# ATmega2564RFR2 register map
Vendor: Atmel; File version: 1.0
CPU: other r0p0, little endian, no MPU, no FPU, 4 interrupt priority bits
Registers are 8-bit, read-write, reset 0x0 unless marked. A register's access mark holds for its fields unless they carry their own. Offsets are from the block's base; [hi:lo] are bit positions; 'fields as' and 'values as' point back to an identical list.

## TC1 — Timer/Counter, 16-bit
Base 0x00800036
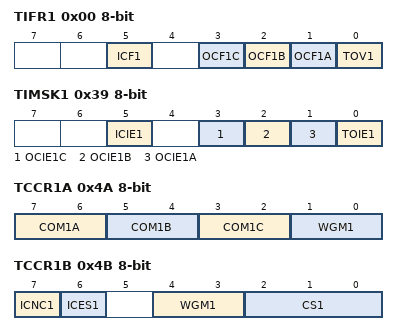
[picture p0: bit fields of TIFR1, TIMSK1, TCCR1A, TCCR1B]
0x00 TIFR1 — Timer/Counter1 Interrupt Flag Register (read-only for debugger)
  [5] ICF1 — Timer/Counter1 Input Capture Flag
  [3] OCF1C — Timer/Counter1 Output Compare C Match Flag
  [2] OCF1B — Timer/Counter1 Output Compare B Match Flag
  [1] OCF1A — Timer/Counter1 Output Compare A Match Flag
  [0] TOV1 — Timer/Counter1 Overflow Flag
0x39 TIMSK1 — Timer/Counter1 Interrupt Mask Register
  [5] ICIE1 — Timer/Counter1 Input Capture Interrupt Enable
  [3] OCIE1C — Timer/Counter1 Output Compare C Match Interrupt Enable
  [2] OCIE1B — Timer/Counter1 Output Compare B Match Interrupt Enable
  [1] OCIE1A — Timer/Counter1 Output Compare A Match Interrupt Enable
  [0] TOIE1 — Timer/Counter1 Overflow Interrupt Enable
0x4A TCCR1A — Timer/Counter1 Control Register A
  [7:6] COM1A — Compare Output Mode for Channel A
    0=NORMAL_PORT_OPERATION_OCNA_OCNB_OCNC_DISCONNECTED; 1=TOGGLE_OCNA_OCNB_OCNC_ON_COMPARE_MATCH; 2=CLEAR_OCNA_OCNB_OCNC_ON_COMPARE_MATCH_SET_OUTPUT_TO_LOW_LEVEL; 3=SET_OCNA_OCNB_OCNC_ON_COMPARE_MATCH_SET_OUTPUT_TO_HIGH_LEVEL
  [5:4] COM1B — Compare Output Mode for Channel B
    values as COM1A
  [3:2] COM1C — Compare Output Mode for Channel C
    values as COM1A
  [1:0] WGM1 — Waveform Generation Mode
    0=NORMAL_MODE_OF_OPERATION; 1=PWM_PHASE_CORRECT_8_BIT; 2=PWM_PHASE_CORRECT_9_BIT; 3=PWM_PHASE_CORRECT_10_BIT
0x4B TCCR1B — Timer/Counter1 Control Register B
  [7] ICNC1 — Input Capture 1 Noise Canceller
  [6] ICES1 — Input Capture 1 Edge Select
  [4:3] WGM1 — Waveform Generation Mode
    values as TCCR1A.WGM1
  [2:0] CS1 — Clock Select
    0=NO_CLOCK_SOURCE_TIMER_COUNTER_STOPPED; 1=CLK_IO_1_NO_PRESCALING; 2=CLK_IO_8_FROM_PRESCALER; 3=CLK_IO_64_FROM_PRESCALER; 4=CLK_IO_256_FROM_PRESCALER; 5=CLK_IO_1024_FROM_PRESCALER; 6=EXTERNAL_CLOCK_SOURCE_ON_TN_PIN_CLOCK_ON_FALLING_EDGE; 7=EXTERNAL_CLOCK_SOURCE_ON_TN_PIN_CLOCK_ON_RISING_EDGE
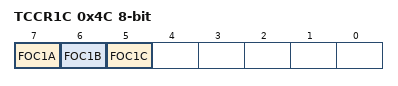
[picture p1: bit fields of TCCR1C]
0x4C TCCR1C — Timer/Counter1 Control Register C
  [7] FOC1A — Force Output Compare for Channel A
  [6] FOC1B — Force Output Compare for Channel B
  [5] FOC1C — Force Output Compare for Channel C
0x4E TCNT1 16-bit (reset mask 0xFF) — Timer/Counter1 Bytes
0x50 ICR1 16-bit (reset mask 0xFF) — Timer/Counter1 Input Capture Register Bytes
0x52 OCR1A 16-bit (reset mask 0xFF) — Timer/Counter1 Output Compare Register A Bytes
0x54 OCR1B 16-bit (reset mask 0xFF) — Timer/Counter1 Output Compare Register B Bytes
0x56 OCR1C 16-bit (reset mask 0xFF) — Timer/Counter1 Output Compare Register C Bytes

## TC2 — Timer/Counter, 8-bit Async
Base 0x00800037
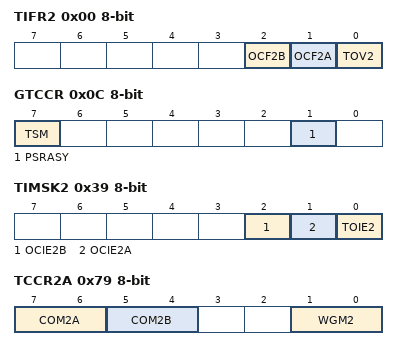
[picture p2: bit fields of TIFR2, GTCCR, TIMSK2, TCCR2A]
0x00 TIFR2 — Timer/Counter Interrupt Flag Register (read-only for debugger)
  [2] OCF2B — Output Compare Flag 2 B
  [1] OCF2A — Output Compare Flag 2 A
  [0] TOV2 — Timer/Counter2 Overflow Flag
0x0C GTCCR — General Timer Counter Control register
  [7] TSM — Timer/Counter Synchronization Mode
  [1] PSRASY — Prescaler Reset Timer/Counter2
0x39 TIMSK2 — Timer/Counter Interrupt Mask register
  [2] OCIE2B — Timer/Counter2 Output Compare Match B Interrupt Enable
  [1] OCIE2A — Timer/Counter2 Output Compare Match A Interrupt Enable
  [0] TOIE2 — Timer/Counter2 Overflow Interrupt Enable
0x79 TCCR2A — Timer/Counter2 Control Register A
  [7:6] COM2A — Compare Match Output A Mode
    0=NORMAL_PORT_OPERATION_OC2A_DISCONNECTED; 1=TOGGLE_OC2A_ON_COMPARE_MATCH; 2=CLEAR_OC2A_ON_COMPARE_MATCH; 3=SET_OC2A_ON_COMPARE_MATCH
  [5:4] COM2B — Compare Match Output B Mode
    0=NORMAL_PORT_OPERATION_OC2B_DISCONNECTED; 1=TOGGLE_OC2B_ON_COMPARE_MATCH; 2=CLEAR_OC2B_ON_COMPARE_MATCH; 3=SET_OC2B_ON_COMPARE_MATCH
  [1:0] WGM2 — Waveform Generation Mode
    0=NORMAL_MODE_OF_OPERATION; 1=PWM_PHASE_CORRECT_TOP_0XFF; 2=CTC_TOP_OCRA; 3=FAST_PWM_TOP_0XFF
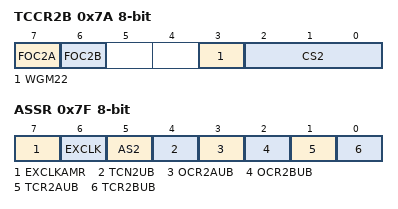
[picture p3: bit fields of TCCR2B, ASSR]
0x7A TCCR2B — Timer/Counter2 Control Register B
  [7] FOC2A — Force Output Compare A
  [6] FOC2B — Force Output Compare B
  [3] WGM22 — Waveform Generation Mode
  [2:0] CS2 — Clock Select
    0=NO_CLOCK_SOURCE_TIMER_COUNTER2_STOPPED; 1=CLK_T2S_1_NO_PRESCALING; 2=CLK_T2S_8_FROM_PRESCALER; 3=CLK_T2S_32_FROM_PRESCALER; 4=CLK_T2S_64_FROM_PRESCALER; 5=CLK_T2S_128_FROM_PRESCALER; 6=CLK_T2S_256_FROM_PRESCALER; 7=CLK_T2S_1024_FROM_PRESCALER
0x7B TCNT2 — Timer/Counter2
0x7C OCR2A — Timer/Counter2 Output Compare Register A
0x7D OCR2B — Timer/Counter2 Output Compare Register B
0x7F ASSR — Asynchronous Status Register
  [7] EXCLKAMR — Enable External Clock Input for AMR
  [6] EXCLK — Enable External Clock Input
  [5] AS2 — Timer/Counter2 Asynchronous Mode
  [4] TCN2UB — Timer/Counter2 Update Busy
  [3] OCR2AUB — Timer/Counter2 Output Compare Register A Update Busy
  [2] OCR2BUB — Timer/Counter2 Output Compare Register B Update Busy
  [1] TCR2AUB — Timer/Counter2 Control Register A Update Busy
  [0] TCR2BUB — Timer/Counter2 Control Register B Update Busy
